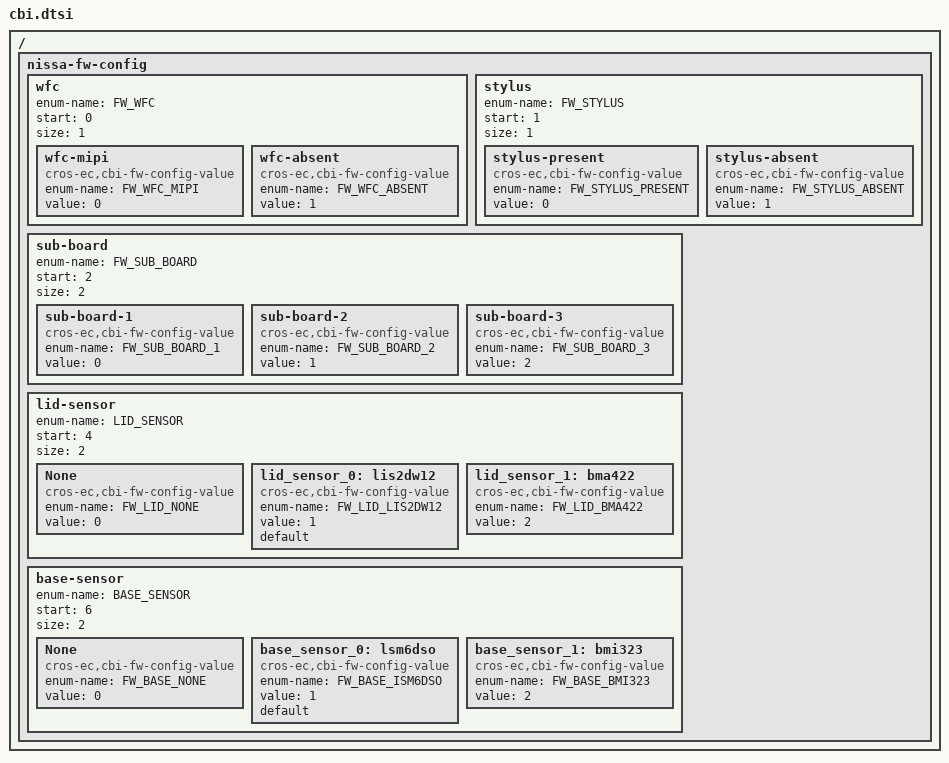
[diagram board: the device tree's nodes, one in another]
/* Copyright 2022 The ChromiumOS Authors
 * Use of this source code is governed by a BSD-style license that can be
 * found in the LICENSE file.
 */

/ {
	/* Xivu-specific fw_config fields. */
	nissa-fw-config {
		/*
		 * FW_CONFIG field to enable WFC or not.
		 */
		 wfc {
			enum-name = "FW_WFC";
			start = <0>;
			size = <1>;

			wfc-mipi {
				compatible = "cros-ec,cbi-fw-config-value";
				enum-name = "FW_WFC_MIPI";
				value = <0>;
			};
			wfc-absent {
				compatible = "cros-ec,cbi-fw-config-value";
				enum-name = "FW_WFC_ABSENT";
				value = <1>;
			};
		 };

		/*
		 * FW_CONFIG field to enable stylus or not.
		 */
		 stylus {
			enum-name = "FW_STYLUS";
			start = <1>;
			size = <1>;

			stylus-present {
				compatible = "cros-ec,cbi-fw-config-value";
				enum-name = "FW_STYLUS_PRESENT";
				value = <0>;
			};
			stylus-absent {
				compatible = "cros-ec,cbi-fw-config-value";
				enum-name = "FW_STYLUS_ABSENT";
				value = <1>;
			};
		 };
		/*
		 * FW_CONFIG field to indicate which sub-board
		 * is attached.
		 */
		sub-board {
			enum-name = "FW_SUB_BOARD";
			start = <2>;
			size = <2>;

			sub-board-1 {
				compatible = "cros-ec,cbi-fw-config-value";
				enum-name = "FW_SUB_BOARD_1";
				value = <0>;
			};
			sub-board-2 {
				compatible = "cros-ec,cbi-fw-config-value";
				enum-name = "FW_SUB_BOARD_2";
				value = <1>;
			};
			sub-board-3 {
				compatible = "cros-ec,cbi-fw-config-value";
				enum-name = "FW_SUB_BOARD_3";
				value = <2>;
			};
		};

		lid-sensor {
			enum-name = "LID_SENSOR";
			start = <4>;
			size = <2>;

			None {
				compatible = "cros-ec,cbi-fw-config-value";
				enum-name = "FW_LID_NONE";
				value = <0>;
			};
			lid_sensor_0: lis2dw12 {
				compatible = "cros-ec,cbi-fw-config-value";
				enum-name = "FW_LID_LIS2DW12";
				value = <1>;
				default;
			};
			lid_sensor_1: bma422 {
				compatible = "cros-ec,cbi-fw-config-value";
				enum-name = "FW_LID_BMA422";
				value = <2>;
			};
		};

		base-sensor {
			enum-name = "BASE_SENSOR";
			start = <6>;
			size = <2>;

			None {
				compatible = "cros-ec,cbi-fw-config-value";
				enum-name = "FW_BASE_NONE";
				value = <0>;
			};
			base_sensor_0: lsm6dso {
				compatible = "cros-ec,cbi-fw-config-value";
				enum-name = "FW_BASE_ISM6DSO";
				value = <1>;
				default;
			};
			base_sensor_1: bmi323 {
				compatible = "cros-ec,cbi-fw-config-value";
				enum-name = "FW_BASE_BMI323";
				value = <2>;
			};
		};

/delete-node/ fan;
	};

};
